AUTOSAR XML (schema 4-0-3)
standard types defined: Boolean, UInt32, UInt8
package /AUTOSAR_Platform/DataConstrs
  range DC_Boolean: raw 0..1
  range DC_UInt8: raw 0..255
package /PATAC/MSM/ComponentTypes
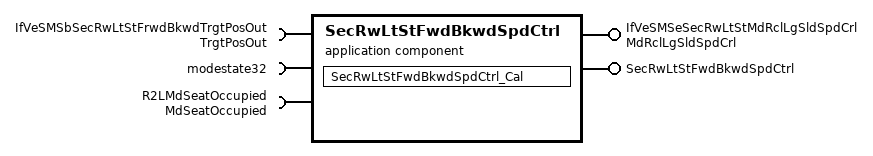
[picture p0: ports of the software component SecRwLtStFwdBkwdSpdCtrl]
  application sw component type SecRwLtStFwdBkwdSpdCtrl
    provide port IfVeSMSeSecRwLtStMdRclLgSldSpdCrl: nonqueued-sender-com-spec{data-element=MdRclLgSldSpdCrl/Val, init-value=0}, provided-interface=MdRclLgSldSpdCrl
    provide port SecRwLtStFwdBkwdSpdCtrl: server-com-spec{operation=Cal, queue-length=1}, provided-interface=SecRwLtStFwdBkwdSpdCtrl
    require port IfVeSMSbSecRwLtStFrwdBkwdTrgtPosOut: nonqueued-receiver-com-spec{data-element=TrgtPosOut/Val, filter=data-filter-type=ALWAYS, init-value=0}, required-interface=TrgtPosOut
    require port modestate32: nonqueued-receiver-com-spec{data-element=modestate32/Val, filter=data-filter-type=ALWAYS, init-value=0}, required-interface=modestate32
    require port R2LMdSeatOccupied: nonqueued-receiver-com-spec{data-element=MdSeatOccupied/Val, filter=data-filter-type=ALWAYS, init-value=0}, required-interface=MdSeatOccupied
    behavior SecRwLtStFwdBkwdSpdCtrl_InternalBehavior
      operation invoked event OIT_SecRwLtStFwdBkwdSpdCtrl_Cal_SecRwLtStFwdBkwdSpdCtrl_Cal: start-on-event=SecRwLtStFwdBkwdSpdCtrl_Cal, operation=SecRwLtStFwdBkwdSpdCtrl.Cal
      runnable SecRwLtStFwdBkwdSpdCtrl_Cal
        data-receive-point-by-arguments:
          access REC_IfVeSMSbSecRwLtStFrwdBkwdTrgtPosOut_Val: accessed-variable=IfVeSMSbSecRwLtStFrwdBkwdTrgtPosOut.Val
          access REC_modestate32_Val: accessed-variable=modestate32.Val
          access REC_R2LMdSeatOccupied_Val: accessed-variable=R2LMdSeatOccupied.Val
        data-send-points:
          access SEND_IfVeSMSeSecRwLtStMdRclLgSldSpdCrl_Val: accessed-variable=IfVeSMSeSecRwLtStMdRclLgSldSpdCrl.Val
  swc implementation SecRwLtStFwdBkwdSpdCtrl_Implementation: behavior=SecRwLtStFwdBkwdSpdCtrl_InternalBehavior
    code-descriptors:
      code Default: artifact-descriptors=autosar-engineering-object={short-label=Default, category=SWSRC}
package /PATAC/MSM/ModeAdjust/PortInterface
  client server interface SecRwLtStFwdBkwdSpdCtrl
    operation Cal
  4 x sender receiver interface:
    MdRclLgSldSpdCrl: invalidation-policy{data-element=MdRclLgSldSpdCrl/Val, handle-invalid=DONT-INVALIDATE}
      data Val: type=UInt8
    MdSeatOccupied: invalidation-policy{data-element=MdSeatOccupied/Val, handle-invalid=DONT-INVALIDATE}
      data Val: type=Boolean
    modestate32: invalidation-policy{data-element=modestate32/Val, handle-invalid=DONT-INVALIDATE}
      data Val: type=UInt32
    TrgtPosOut: invalidation-policy{data-element=TrgtPosOut/Val, handle-invalid=DONT-INVALIDATE}
      data Val: type=Boolean
